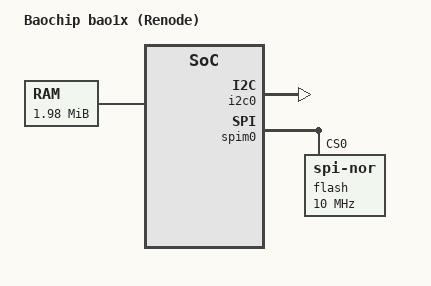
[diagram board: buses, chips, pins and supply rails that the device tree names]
/*
 * Baochip-1x on the Renode emulation platform (emulation/renode/bao1x.repl).
 * Differs from silicon only in clocking: mcycle advances at Renode's
 * virtual 100 MIPS (cpu PerformanceInMips), so timebase-frequency is
 * 100MHz here and 350MHz on the Dabao board.
 *
 * SPDX-License-Identifier: GPL-2.0 OR MIT
 */
/dts-v1/;

/include/ "bao1x.dtsi"

/ {
	model = "Baochip bao1x (Renode)";

	aliases {
		serial0 = &uart2;
	};

	chosen {
		/* Bare "earlycon" resolves via stdout-path to the DUART;
		 * the real console is the uDMA UART2 driver. */
		bootargs = "earlycon console=ttyBAO0 root=mtd:rootfs rootfstype=cramfs ro";
		stdout-path = &duart;
	};

	cpus {
		timebase-frequency = <100000000>;
	};

	perclk: clock-perclk {
		compatible = "fixed-clock";
		#clock-cells = <0>;
		clock-frequency = <100000000>;
	};

	memory@61000000 {
		device_type = "memory";
		/* 2MiB SRAM minus the top 16KiB (bao1x-sbi workspace). */
		reg = <0x61000000 0x1fc000>;
	};
};

&uart2 {
	/* Renode Bao1xUdmaUart model clock (silicon perclk differs). */
	clock-frequency = <100000000>;
};

&i2c0 {
	status = "okay";
	clocks = <&perclk>;
};

&spim0 {
	status = "okay";
	clocks = <&perclk>;

	flash@0 {
		/* Renode Micron_MT25Q model on CS0 (linux.robot). */
		compatible = "jedec,spi-nor";
		reg = <0>;
		spi-max-frequency = <10000000>;
	};
};

&data_part {
	/* Small in emulation: every byte is a slow peripheral access in
	 * Renode, and JFFS2 scans the whole partition at mount. */
	reg = <0x360000 0x20000>;
};
